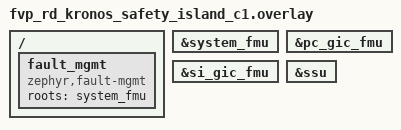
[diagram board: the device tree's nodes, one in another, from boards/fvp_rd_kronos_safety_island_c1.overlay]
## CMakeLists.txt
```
# SPDX-FileCopyrightText: <text>Copyright 2023 Arm Limited and/or its
# affiliates <open-source-office@arm.com></text>
#
# SPDX-License-Identifier: Apache-2.0

cmake_minimum_required(VERSION 3.23.0)

find_package(Zephyr REQUIRED HINTS $ENV{ZEPHYR_BASE})

project(fault_mgmt)

target_sources(app PRIVATE
  src/main.c
)
```

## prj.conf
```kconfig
# SPDX-FileCopyrightText: <text>Copyright 2023-2024 Arm Limited and/or its
# affiliates <open-source-office@arm.com></text>
#
# SPDX-License-Identifier: Apache-2.0

CONFIG_COMPILER_WARNINGS_AS_ERRORS=y
CONFIG_SHELL_STACK_SIZE=4096

CONFIG_FAULT_MGMT=y
CONFIG_FAULT_MGMT_SAFETY=y
CONFIG_FAULT_MGMT_SHELL=y
CONFIG_FAULT_MGMT_STACK_SIZE=2048
CONFIG_FAULT_MGMT_ARM_FMU=y
CONFIG_FAULT_MGMT_ARM_SSU=y

CONFIG_LOG=y

CONFIG_FAULT_MGMT_STORAGE=y
CONFIG_FAULT_MGMT_PSA_PROTECTED_STORAGE=y
CONFIG_COMMON_LIBC_MALLOC_ARENA_SIZE=3072

CONFIG_DEVICE_DEPS=y
```

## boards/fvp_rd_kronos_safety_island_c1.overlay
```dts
/*
 * SPDX-FileCopyrightText: <text>Copyright 2023-2024 Arm Limited and/or its
 * affiliates <open-source-office@arm.com></text>
 *
 * SPDX-License-Identifier: Apache-2.0
 */

/ {
	fault_mgmt {
		compatible = "zephyr,fault-mgmt";
		roots = <&system_fmu>;
		status = "okay";
	};
};

&system_fmu {
	status = "okay";
};

&pc_gic_fmu {
	status = "okay";
};

&si_gic_fmu {
	status = "okay";
};

&ssu {
	status = "okay";
};
```

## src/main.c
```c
/*
 * SPDX-FileCopyrightText: <text>Copyright 2023 Arm Limited and/or its
 * affiliates <open-source-office@arm.com></text>
 *
 * SPDX-License-Identifier: Apache-2.0
 */

int main(void)
{
	return 0;
}
```
